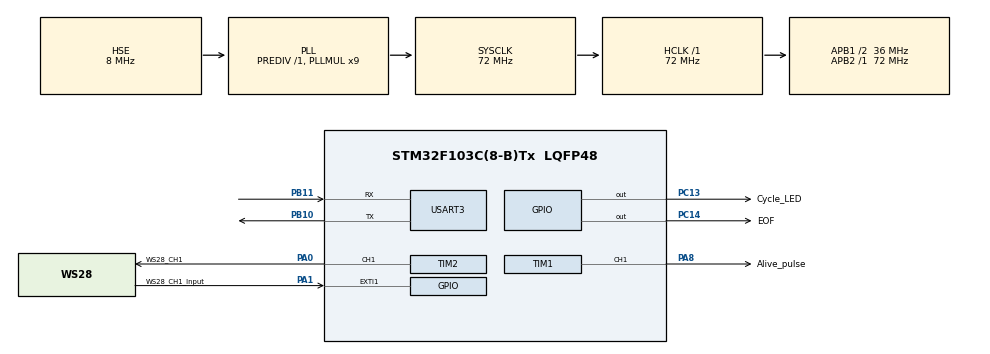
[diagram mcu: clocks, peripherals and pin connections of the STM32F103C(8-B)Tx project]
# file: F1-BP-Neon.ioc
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Mcu.Family=STM32F1
Dma.USART3_RX.0.Instance=DMA1_Channel3
RCC.PLLSourceVirtual=RCC_PLLSOURCE_HSE
Dma.USART3_TX.1.MemDataAlignment=DMA_MDATAALIGN_BYTE
Dma.TIM2_CH1.2.MemInc=DMA_MINC_ENABLE
Dma.TIM2_CH1.2.PeriphDataAlignment=DMA_PDATAALIGN_WORD
Dma.USART3_RX.0.PeriphInc=DMA_PINC_DISABLE
NVIC.DMA1_Channel5_IRQn=true\:0\:0\:false\:false\:true\:false\:true
PD1-OSC_OUT.Mode=HSE-External-Oscillator
PB10.Mode=Asynchronous
Dma.USART3_TX.1.MemInc=DMA_MINC_ENABLE
Dma.USART3_TX.1.PeriphDataAlignment=DMA_PDATAALIGN_BYTE
PC13-TAMPER-RTC.Signal=GPIO_Output
PD0-OSC_IN.Signal=RCC_OSC_IN
TIM1.Pulse-PWM\ Generation1\ CH1=1000
Dma.USART3_TX.1.Instance=DMA1_Channel2
RCC.APB1CLKDivider=RCC_HCLK_DIV2
PC14-OSC32_IN.Signal=GPIO_Output
PB11.Signal=USART3_RX
RCC.SYSCLKSource=RCC_SYSCLKSOURCE_PLLCLK
ProjectManager.StackSize=0x400
PA0-WKUP.GPIO_Label=WS28_CH1
Dma.USART3_RX.0.Mode=DMA_NORMAL
PA0-WKUP.Signal=S_TIM2_CH1_ETR
PD1-OSC_OUT.Signal=RCC_OSC_OUT
NVIC.DMA1_Channel3_IRQn=true\:0\:0\:false\:false\:true\:false\:true
PA13.Signal=SYS_JTMS-SWDIO
Dma.TIM2_CH1.2.Mode=DMA_CIRCULAR
Dma.TIM2_CH1.2.PeriphInc=DMA_PINC_DISABLE
NVIC.EXTI1_IRQn=true\:0\:0\:false\:false\:true\:true\:true
PA8.GPIO_Label=Alive_pulse
TIM1.Prescaler=7200
SH.S_TIM1_CH1.0=TIM1_CH1,PWM Generation1 CH1
Dma.TIM2_CH1.2.MemDataAlignment=DMA_MDATAALIGN_WORD
PB11.Mode=Asynchronous
NVIC.DMA1_Channel2_IRQn=true\:0\:0\:false\:false\:true\:false\:true
ProjectManager.TargetToolchain=Makefile
RCC.HCLKFreq_Value=72000000
RCC.APB2TimFreq_Value=72000000
TIM3.Period=269
RCC.USBFreq_Value=72000000
PA1.Signal=GPXTI1
RCC.AHBFreq_Value=72000000
PD0-OSC_IN.Mode=HSE-External-Oscillator
PB10.Signal=USART3_TX
Dma.USART3_RX.0.MemDataAlignment=DMA_MDATAALIGN_BYTE
Dma.TIM2_CH1.2.Priority=DMA_PRIORITY_VERY_HIGH
board=custom
Dma.USART3_TX.1.Mode=DMA_NORMAL
PC13-TAMPER-RTC.GPIO_Label=Cycle_LED
RCC.PLLMUL=RCC_PLL_MUL9
NVIC.TIM3_IRQn=true\:0\:0\:false\:false\:true\:true\:true
RCC.APB2Freq_Value=72000000
TIM1.Channel-PWM\ Generation1\ CH1=TIM_CHANNEL_1
PA14.Mode=Serial_Wire
PA1.GPIO_Label=WS28_CH1_Input
Dma.USART3_RX.0.PeriphDataAlignment=DMA_PDATAALIGN_BYTE
PA8.Signal=S_TIM1_CH1
TIM2.Channel-PWM\ Generation1\ CH1=TIM_CHANNEL_1
TIM2.Period=89
PC13-TAMPER-RTC.GPIO_Speed=GPIO_SPEED_FREQ_HIGH
PA13.Mode=Serial_Wire
Mcu.Name=STM32F103C(8-B)Tx
Dma.USART3_TX.1.Priority=DMA_PRIORITY_LOW
PC14-OSC32_IN.GPIO_Speed=GPIO_SPEED_FREQ_HIGH
RCC.SYSCLKFreq_VALUE=72000000
Dma.USART3_RX.0.Direction=DMA_PERIPH_TO_MEMORY
Mcu.Package=LQFP48
Dma.USART3_RX.0.Priority=DMA_PRIORITY_LOW
Dma.TIM2_CH1.2.Direction=DMA_MEMORY_TO_PERIPH
USART3.VirtualMode=VM_ASYNC
SH.S_TIM2_CH1_ETR.0=TIM2_CH1,PWM Generation1 CH1
PA14.Signal=SYS_JTCK-SWCLK
ProjectManager.HeapSize=0x200
Dma.USART3_RX.0.MemInc=DMA_MINC_ENABLE
NVIC.PriorityGroup=NVIC_PRIORITYGROUP_4
Dma.USART3_TX.1.Direction=DMA_MEMORY_TO_PERIPH
Dma.Request2=TIM2_CH1
Dma.Request1=USART3_TX
RCC.APB1TimFreq_Value=72000000
PC14-OSC32_IN.GPIO_Label=EOF
TIM1.Period=10000
Dma.USART3_TX.1.PeriphInc=DMA_PINC_DISABLE
Dma.Request0=USART3_RX
RCC.APB1Freq_Value=36000000
VP_TIM3_VS_ClockSourceINT.Mode=Internal
Dma.TIM2_CH1.2.Instance=DMA1_Channel5

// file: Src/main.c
/* USER CODE BEGIN Header */

/**
 ******************************************************************************
 * @file           : main.c
 * @brief          : Main program body
 ******************************************************************************
 * @attention
 *
 * <h2><center>&copy; Copyright (c) 2021 STMicroelectronics.
 * All rights reserved.</center></h2>
 *
 * This software component is licensed by ST under BSD 3-Clause license,
 * the "License"; You may not use this file except in compliance with the
 * License. You may obtain a copy of the License at:
 *                        opensource.org/licenses/BSD-3-Clause
 *
 ******************************************************************************
 */

/* USER CODE END Header */
#include "dma.h"
#include "gpio.h"
#include "main.h"
#include "tim.h"
#include "usart.h"

/* USER CODE BEGIN Includes */
#include "neon.h"

/* USER CODE END Includes */

void SystemClock_Config(void);

int main(void)
{

    /* MCU Configuration--------------------------------------------------------*/

    /* Reset of all peripherals, Initializes the Flash interface and the Systick. */
    HAL_Init();

    /* Configure the system clock */
    SystemClock_Config();

    /* Initialize all configured peripherals */
    MX_DMA_Init();
    MX_TIM1_Init();
    MX_TIM2_Init();
    MX_TIM3_Init();
    MX_USART3_UART_Init();

    /* USER CODE BEGIN 2 */
    neon_main();

    /* USER CODE END 2 */

    /* Infinite loop */
    while (1) {

    }
}

void SystemClock_Config(void)
{
    RCC_OscInitTypeDef RCC_OscInitStruct = {0};
    RCC_ClkInitTypeDef RCC_ClkInitStruct = {0};

    /** Initializes the RCC Oscillators according to the specified parameters
     * in the RCC_OscInitTypeDef structure.
     */
    RCC_OscInitStruct.OscillatorType = RCC_OSCILLATORTYPE_HSE;
    RCC_OscInitStruct.HSEState = RCC_HSE_ON;
    RCC_OscInitStruct.HSEPredivValue = RCC_HSE_PREDIV_DIV1;
    RCC_OscInitStruct.HSIState = RCC_HSI_ON;
    RCC_OscInitStruct.PLL.PLLState = RCC_PLL_ON;
    RCC_OscInitStruct.PLL.PLLSource = RCC_PLLSOURCE_HSE;
    RCC_OscInitStruct.PLL.PLLMUL = RCC_PLL_MUL9;
    if (HAL_RCC_OscConfig(&RCC_OscInitStruct) != HAL_OK) {
        Error_Handler();
    }

    /** Initializes the CPU, AHB and APB buses clocks
     */
    RCC_ClkInitStruct.ClockType = RCC_CLOCKTYPE_HCLK | RCC_CLOCKTYPE_SYSCLK |
                                  RCC_CLOCKTYPE_PCLK1 | RCC_CLOCKTYPE_PCLK2;
    RCC_ClkInitStruct.SYSCLKSource = RCC_SYSCLKSOURCE_PLLCLK;
    RCC_ClkInitStruct.AHBCLKDivider = RCC_SYSCLK_DIV1;
    RCC_ClkInitStruct.APB1CLKDivider = RCC_HCLK_DIV2;
    RCC_ClkInitStruct.APB2CLKDivider = RCC_HCLK_DIV1;

    if (HAL_RCC_ClockConfig(&RCC_ClkInitStruct, FLASH_LATENCY_2) != HAL_OK) {
        Error_Handler();
    }
}

void Error_Handler(void)
{
    __disable_irq();
    while (1) {
    }
}

/************************ (C) COPYRIGHT STMicroelectronics *****END OF FILE****/
